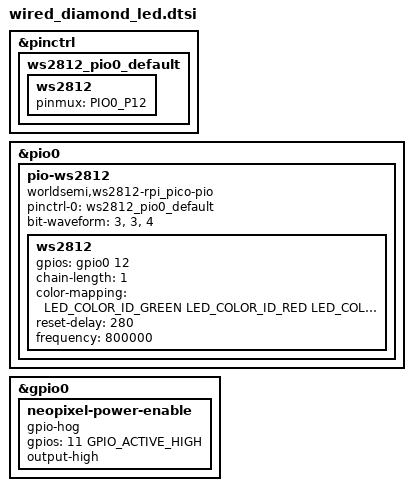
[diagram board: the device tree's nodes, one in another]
#include <dt-bindings/led/led.h>

&pinctrl {
	ws2812_pio0_default: ws2812_pio0_default {
		ws2812 {
			pinmux = <PIO0_P12>;
		};
	};
};

&pio0 {
	status = "okay";

	pio-ws2812 {
		compatible = "worldsemi,ws2812-rpi_pico-pio";
		status = "okay";
		pinctrl-0 = <&ws2812_pio0_default>;
		pinctrl-names = "default";
		bit-waveform = <3>, <3>, <4>;

		ws2812: ws2812 {
            status = "okay";
            gpios = <&gpio0 12 GPIO_ACTIVE_HIGH>;
            chain-length = <1>;
            color-mapping = <LED_COLOR_ID_GREEN
            		LED_COLOR_ID_RED
            		LED_COLOR_ID_BLUE>;
            reset-delay = <280>;
            frequency = <800000>;
		};
	};
};

&gpio0 {
	status = "okay";

	/*
	 * The neopixel on this board has its positive side hooked up to a GPIO pin
	 * rather than a positive voltage rail to save on power. This will enable
	 * the LED on board initialization.
	 */
	neopixel-power-enable {
		gpio-hog;
		gpios = <11 GPIO_ACTIVE_HIGH>;
		output-high;
	};
};
